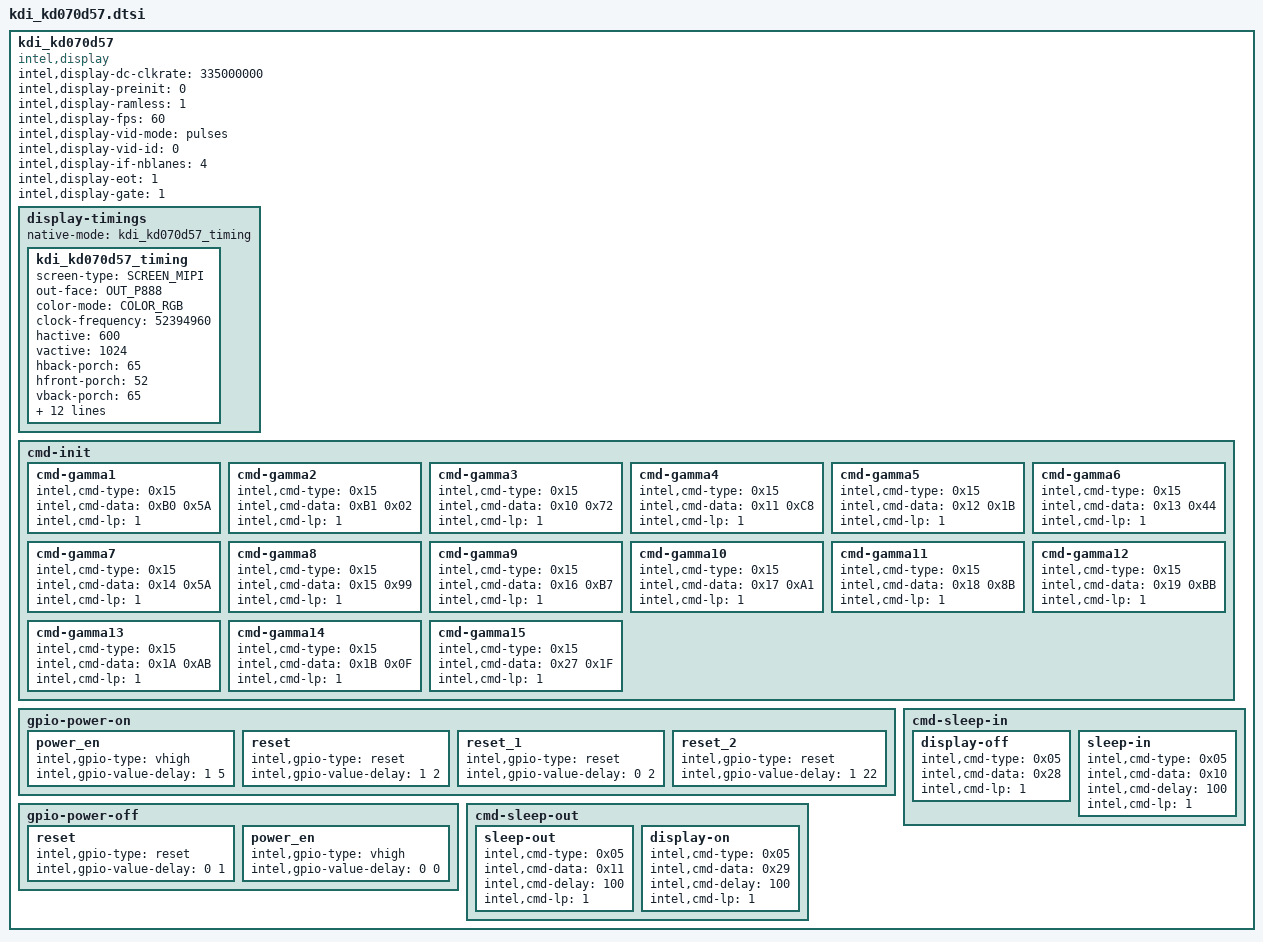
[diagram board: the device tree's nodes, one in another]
/*
 * definition at "include/dt-bindings/sofiafb/sofia_fb.h"
 */


kdi_kd070d57 {
	compatible = "intel,display";
	intel,display-dc-clkrate = <335000000>;
	intel,display-preinit = <0>;
	intel,display-ramless = <1>;
	intel,display-fps = <60>;
	intel,display-vid-mode = "pulses";
	intel,display-vid-id = <0>;
	intel,display-if-nblanes = <4>;
	intel,display-eot = <1>;
	intel,display-gate = <1>;

	display-timings {
		native-mode = <&kdi_kd070d57_timing>;
		kdi_kd070d57_timing: kdi_kd070d57_timing {
			screen-type = <SCREEN_MIPI>;
			out-face    = <OUT_P888>;
			color-mode = <COLOR_RGB>;
			clock-frequency = <52394960>;
			hactive = <600>;
			vactive = <1024>;
			hback-porch = <65>;
			hfront-porch = <52>;
			vback-porch = <65>;
			vfront-porch = <52>;
			hsync-len = <24>;
			vsync-len = <2>;
			hsync-active = <0>;
			vsync-active = <0>;
			de-active = <0>;
			pixelclk-active = <0>;
			swap-rb = <0>;
			swap-rg = <0>;
			swap-gb = <0>;
			width = <89>;
			height = <152>;
		};
	};
	cmd-init{
                cmd-gamma1{
                        intel,cmd-type = <0x15>;
                        intel,cmd-data = <0xB0 0x5A>;
                        intel,cmd-lp = <1>;
                };
                cmd-gamma2{
                        intel,cmd-type = <0x15>;
                        intel,cmd-data = <0xB1 0x02>;
                        intel,cmd-lp = <1>;
                };

                cmd-gamma3{
                        intel,cmd-type = <0x15>;
                        intel,cmd-data = <0x10 0x72>;
                        intel,cmd-lp = <1>;
                };

                cmd-gamma4{
                        intel,cmd-type = <0x15>;
                        intel,cmd-data = <0x11 0xC8>;
                        intel,cmd-lp = <1>;
                };

                cmd-gamma5{
                        intel,cmd-type = <0x15>;
                        intel,cmd-data = <0x12 0x1B>;
                        intel,cmd-lp = <1>;
                };

                cmd-gamma6{
                        intel,cmd-type = <0x15>;
                        intel,cmd-data = <0x13 0x44>;
                        intel,cmd-lp = <1>;
                };
                cmd-gamma7{
                        intel,cmd-type = <0x15>;
                        intel,cmd-data = <0x14 0x5A>;
                        intel,cmd-lp = <1>;
                };
                cmd-gamma8{
                        intel,cmd-type = <0x15>;
                        intel,cmd-data = <0x15 0x99>;
                        intel,cmd-lp = <1>;
                };
                cmd-gamma9{
                        intel,cmd-type = <0x15>;
                        intel,cmd-data = <0x16 0xB7>;
                        intel,cmd-lp = <1>;
                };
                cmd-gamma10{
                        intel,cmd-type = <0x15>;
                        intel,cmd-data = <0x17 0xA1>;
                        intel,cmd-lp = <1>;
                };
                cmd-gamma11{
                        intel,cmd-type = <0x15>;
                        intel,cmd-data = <0x18 0x8B>;
                        intel,cmd-lp = <1>;
                };
                cmd-gamma12{
                        intel,cmd-type = <0x15>;
                        intel,cmd-data = <0x19 0xBB>;
                        intel,cmd-lp = <1>;
                };
                cmd-gamma13{
                        intel,cmd-type = <0x15>;
                        intel,cmd-data = <0x1A 0xAB>;
                        intel,cmd-lp = <1>;
                };
                cmd-gamma14{
                        intel,cmd-type = <0x15>;
                        intel,cmd-data = <0x1B 0x0F>;
                        intel,cmd-lp = <1>;
                };
                cmd-gamma15{
                        intel,cmd-type = <0x15>;
                        intel,cmd-data = <0x27 0x1F>;
                        intel,cmd-lp = <1>;
                };

	};
	gpio-power-on {
		power_en {
				intel,gpio-type = "vhigh";
				intel,gpio-value-delay = <1 5>;
		};

		reset {
			intel,gpio-type = "reset";
			intel,gpio-value-delay = <1 2>;
		};

		reset_1 {
			intel,gpio-type = "reset";
			intel,gpio-value-delay = <0 2>;
		};
		reset_2 {
			intel,gpio-type = "reset";
			intel,gpio-value-delay = <1 22>;
		};
	};

	gpio-power-off {
		reset {
			intel,gpio-type = "reset";
			intel,gpio-value-delay = <0 1>;
		};
		power_en {
			intel,gpio-type = "vhigh";
			intel,gpio-value-delay = <0 0>;
		};
	};

	cmd-sleep-in {
		display-off{
			intel,cmd-type = <0x05>;
			intel,cmd-data = <0x28>;
			intel,cmd-lp = <1>;
		};
		sleep-in{
			intel,cmd-type = <0x05>;
			intel,cmd-data = <0x10>;
			intel,cmd-delay = <100>;
			intel,cmd-lp = <1>;
		};
	};

	cmd-sleep-out {
		sleep-out{
			intel,cmd-type = <0x05>;
			intel,cmd-data = <0x11>;
			intel,cmd-delay = <100>;
			intel,cmd-lp = <1>;
		};
		display-on{
			intel,cmd-type = <0x05>;
			intel,cmd-data = <0x29>;
			intel,cmd-delay = <100>;
			intel,cmd-lp = <1>;
		};
	};
};
